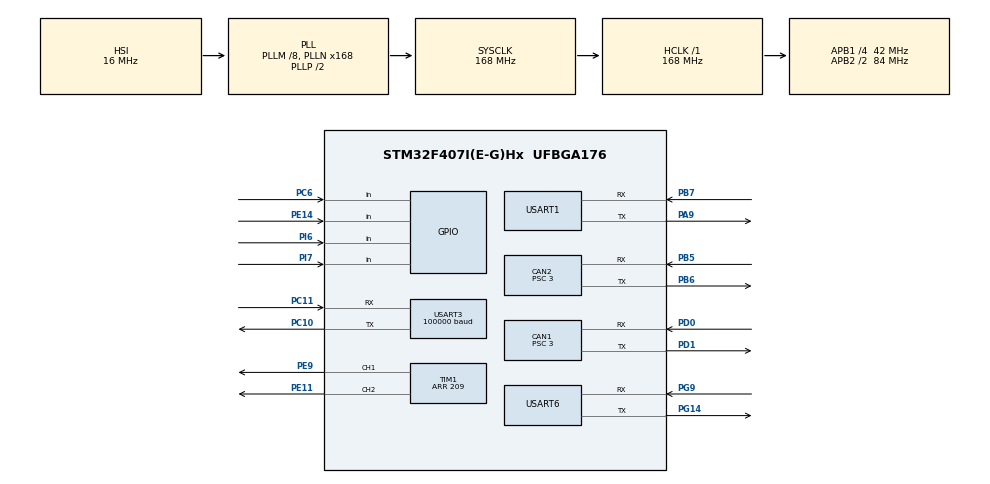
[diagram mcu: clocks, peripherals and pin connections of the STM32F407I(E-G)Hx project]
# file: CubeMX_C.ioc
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CAN1.BS1=CAN_BS1_10TQ
CAN1.BS2=CAN_BS2_3TQ
CAN1.CalculateBaudRate=1000000
CAN1.CalculateTimeBit=1000
CAN1.CalculateTimeQuantum=71.42857142857143
CAN1.Mode=CAN_MODE_NORMAL
CAN1.NART=ENABLE
CAN1.Prescaler=3
CAN1.TXFP=ENABLE
CAN2.BS1=CAN_BS1_10TQ
CAN2.BS2=CAN_BS2_3TQ
CAN2.CalculateBaudRate=1000000
CAN2.CalculateTimeBit=1000
CAN2.CalculateTimeQuantum=71.42857142857143
CAN2.NART=ENABLE
CAN2.Prescaler=3
CAN2.TXFP=ENABLE
Dma.Request0=TIM1_CH1
Dma.Request1=TIM1_CH2
Dma.Request2=USART6_RX
Dma.Request3=USART6_TX
Dma.Request4=USART1_RX
Dma.Request5=USART1_TX
Dma.Request6=USART3_RX
Dma.TIM1_CH1.0.Direction=DMA_MEMORY_TO_PERIPH
Dma.TIM1_CH1.0.FIFOMode=DMA_FIFOMODE_DISABLE
Dma.TIM1_CH1.0.Instance=DMA2_Stream3
Dma.TIM1_CH1.0.MemDataAlignment=DMA_MDATAALIGN_HALFWORD
Dma.TIM1_CH1.0.MemInc=DMA_MINC_ENABLE
Dma.TIM1_CH1.0.Mode=DMA_NORMAL
Dma.TIM1_CH1.0.PeriphDataAlignment=DMA_PDATAALIGN_HALFWORD
Dma.TIM1_CH1.0.PeriphInc=DMA_PINC_DISABLE
Dma.TIM1_CH1.0.Priority=DMA_PRIORITY_HIGH
Dma.TIM1_CH2.1.Direction=DMA_MEMORY_TO_PERIPH
Dma.TIM1_CH2.1.FIFOMode=DMA_FIFOMODE_DISABLE
Dma.TIM1_CH2.1.Instance=DMA2_Stream2
Dma.TIM1_CH2.1.MemDataAlignment=DMA_MDATAALIGN_HALFWORD
Dma.TIM1_CH2.1.MemInc=DMA_MINC_ENABLE
Dma.TIM1_CH2.1.Mode=DMA_NORMAL
Dma.TIM1_CH2.1.PeriphDataAlignment=DMA_PDATAALIGN_HALFWORD
Dma.TIM1_CH2.1.PeriphInc=DMA_PINC_DISABLE
Dma.TIM1_CH2.1.Priority=DMA_PRIORITY_HIGH
Dma.USART1_RX.4.Direction=DMA_PERIPH_TO_MEMORY
Dma.USART1_RX.4.FIFOMode=DMA_FIFOMODE_DISABLE
Dma.USART1_RX.4.Instance=DMA2_Stream5
Dma.USART1_RX.4.MemDataAlignment=DMA_MDATAALIGN_BYTE
Dma.USART1_RX.4.MemInc=DMA_MINC_ENABLE
Dma.USART1_RX.4.Mode=DMA_NORMAL
Dma.USART1_RX.4.PeriphDataAlignment=DMA_PDATAALIGN_BYTE
Dma.USART1_RX.4.PeriphInc=DMA_PINC_DISABLE
Dma.USART1_RX.4.Priority=DMA_PRIORITY_MEDIUM
Dma.USART1_TX.5.Direction=DMA_MEMORY_TO_PERIPH
Dma.USART1_TX.5.FIFOMode=DMA_FIFOMODE_DISABLE
Dma.USART1_TX.5.Instance=DMA2_Stream7
Dma.USART1_TX.5.MemDataAlignment=DMA_MDATAALIGN_BYTE
Dma.USART1_TX.5.MemInc=DMA_MINC_ENABLE
Dma.USART1_TX.5.Mode=DMA_NORMAL
Dma.USART1_TX.5.PeriphDataAlignment=DMA_PDATAALIGN_BYTE
Dma.USART1_TX.5.PeriphInc=DMA_PINC_DISABLE
Dma.USART1_TX.5.Priority=DMA_PRIORITY_MEDIUM
Dma.USART3_RX.6.Direction=DMA_PERIPH_TO_MEMORY
Dma.USART3_RX.6.FIFOMode=DMA_FIFOMODE_DISABLE
Dma.USART3_RX.6.Instance=DMA1_Stream1
Dma.USART3_RX.6.MemDataAlignment=DMA_MDATAALIGN_BYTE
Dma.USART3_RX.6.MemInc=DMA_MINC_ENABLE
Dma.USART3_RX.6.Mode=DMA_NORMAL
Dma.USART3_RX.6.PeriphDataAlignment=DMA_PDATAALIGN_BYTE
Dma.USART3_RX.6.PeriphInc=DMA_PINC_DISABLE
Dma.USART3_RX.6.Priority=DMA_PRIORITY_MEDIUM
Dma.USART6_RX.2.Direction=DMA_PERIPH_TO_MEMORY
Dma.USART6_RX.2.FIFOMode=DMA_FIFOMODE_DISABLE
Dma.USART6_RX.2.Instance=DMA2_Stream1
Dma.USART6_RX.2.MemDataAlignment=DMA_MDATAALIGN_BYTE
Dma.USART6_RX.2.MemInc=DMA_MINC_ENABLE
Dma.USART6_RX.2.Mode=DMA_NORMAL
Dma.USART6_RX.2.PeriphDataAlignment=DMA_PDATAALIGN_BYTE
Dma.USART6_RX.2.PeriphInc=DMA_PINC_DISABLE
Dma.USART6_RX.2.Priority=DMA_PRIORITY_MEDIUM
Dma.USART6_TX.3.Direction=DMA_MEMORY_TO_PERIPH
Dma.USART6_TX.3.FIFOMode=DMA_FIFOMODE_DISABLE
Dma.USART6_TX.3.Instance=DMA2_Stream6
Dma.USART6_TX.3.MemDataAlignment=DMA_MDATAALIGN_BYTE
Dma.USART6_TX.3.MemInc=DMA_MINC_ENABLE
Dma.USART6_TX.3.Mode=DMA_NORMAL
Dma.USART6_TX.3.PeriphDataAlignment=DMA_PDATAALIGN_BYTE
Dma.USART6_TX.3.PeriphInc=DMA_PINC_DISABLE
Dma.USART6_TX.3.Priority=DMA_PRIORITY_MEDIUM
FREERTOS.Tasks01=defaultTask,0,128,StartDefaultTask,Default,NULL,Dynamic,NULL,NULL;start_mission_p,-3,512,start_mission_planer_task,As weak,NULL,Dynamic,NULL,NULL
FREERTOS.configTOTAL_HEAP_SIZE=65360
Mcu.Family=STM32F4
Mcu.Name=STM32F407I(E-G)Hx
Mcu.Package=UFBGA176
NVIC.CAN1_RX0_IRQn=true\:5\:0\:true\:false\:true\:true\:true\:true\:true
NVIC.CAN2_RX0_IRQn=true\:5\:0\:true\:false\:true\:true\:true\:true\:true
NVIC.DMA1_Stream1_IRQn=true\:6\:0\:true\:false\:true\:true\:false\:true\:true
NVIC.DMA2_Stream1_IRQn=true\:6\:0\:true\:false\:true\:true\:false\:true\:true
NVIC.DMA2_Stream2_IRQn=true\:6\:0\:true\:false\:true\:true\:false\:true\:true
NVIC.DMA2_Stream3_IRQn=true\:6\:0\:true\:false\:true\:true\:false\:true\:true
NVIC.DMA2_Stream5_IRQn=true\:6\:0\:true\:false\:true\:true\:false\:true\:true
NVIC.DMA2_Stream6_IRQn=true\:6\:0\:true\:false\:true\:true\:false\:true\:true
NVIC.DMA2_Stream7_IRQn=true\:6\:0\:true\:false\:true\:true\:false\:true\:true
NVIC.PriorityGroup=NVIC_PRIORITYGROUP_4
NVIC.TIM1_BRK_TIM9_IRQn=true\:5\:0\:false\:false\:true\:true\:true\:true\:true
NVIC.TIM1_CC_IRQn=true\:5\:0\:false\:false\:true\:true\:true\:true\:true
NVIC.TIM1_TRG_COM_TIM11_IRQn=true\:5\:0\:false\:false\:true\:true\:true\:true\:true
NVIC.TIM1_UP_TIM10_IRQn=true\:5\:0\:false\:false\:true\:true\:true\:true\:true
NVIC.USART1_IRQn=true\:6\:0\:true\:false\:true\:true\:true\:true\:true
NVIC.USART3_IRQn=true\:6\:0\:true\:false\:true\:true\:true\:true\:true
NVIC.USART6_IRQn=true\:6\:0\:true\:false\:true\:true\:true\:true\:true
PA13.Mode=Serial_Wire
PA13.Signal=SYS_JTMS-SWDIO
PA14.Mode=Serial_Wire
PA14.Signal=SYS_JTCK-SWCLK
PA9.Mode=Asynchronous
PA9.Signal=USART1_TX
PB5.Mode=CAN_Activate
PB5.Signal=CAN2_RX
PB6.Mode=CAN_Activate
PB6.Signal=CAN2_TX
PB7.Mode=Asynchronous
PB7.Signal=USART1_RX
PC10.Mode=Asynchronous
PC10.Signal=USART3_TX
PC11.Mode=Asynchronous
PC11.Signal=USART3_RX
PC6.Signal=GPIO_Input
PD0.Mode=CAN_Activate
PD0.Signal=CAN1_RX
PD1.Mode=CAN_Activate
PD1.Signal=CAN1_TX
PE11.Signal=S_TIM1_CH2
PE14.Signal=GPIO_Input
PE9.Signal=S_TIM1_CH1
PG14.Mode=Asynchronous
PG14.Signal=USART6_TX
PG9.Mode=Asynchronous
PG9.Signal=USART6_RX
PH0-OSC_IN.Mode=HSE-External-Oscillator
PH0-OSC_IN.Signal=RCC_OSC_IN
PH1-OSC_OUT.Mode=HSE-External-Oscillator
PH1-OSC_OUT.Signal=RCC_OSC_OUT
PI6.Signal=GPIO_Input
PI7.Signal=GPIO_Input
ProjectManager.HeapSize=0x200
ProjectManager.StackSize=0x400
ProjectManager.TargetToolchain=CMake
RCC.48MHZClocksFreq_Value=84000000
RCC.AHBFreq_Value=168000000
RCC.APB1CLKDivider=RCC_HCLK_DIV4
RCC.APB1Freq_Value=42000000
RCC.APB1TimFreq_Value=84000000
RCC.APB2CLKDivider=RCC_HCLK_DIV2
RCC.APB2Freq_Value=84000000
RCC.APB2TimFreq_Value=168000000
RCC.CortexFreq_Value=168000000
RCC.HCLKFreq_Value=168000000
RCC.HSE_VALUE=25000000
RCC.HSI_VALUE=16000000
RCC.LSE_VALUE=32768
RCC.PLLM=8
RCC.PLLN=168
RCC.SYSCLKFreq_VALUE=168000000
RCC.SYSCLKSource=RCC_SYSCLKSOURCE_PLLCLK
RCC.VCOOutputFreq_Value=336000000
SH.S_TIM1_CH1.0=TIM1_CH1,PWM Generation1 CH1
SH.S_TIM1_CH2.0=TIM1_CH2,PWM Generation2 CH2
TIM1.Channel-PWM\ Generation1\ CH1=TIM_CHANNEL_1
TIM1.Channel-PWM\ Generation2\ CH2=TIM_CHANNEL_2
TIM1.Period=209
USART1.VirtualMode=VM_ASYNC
USART3.BaudRate=100000
USART3.Mode=MODE_RX
USART3.Parity=PARITY_EVEN
USART3.StopBits=STOPBITS_2
USART3.VirtualMode=VM_ASYNC
USART6.VirtualMode=VM_ASYNC
VP_FREERTOS_VS_CMSIS_V1.Mode=CMSIS_V1
VP_RTC_VS_RTC_Activate.Mode=RTC_Enabled
VP_RTC_VS_RTC_Calendar.Mode=RTC_Calendar
VP_TIM1_VS_ClockSourceINT.Mode=Internal
board=custom

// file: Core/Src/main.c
/* USER CODE BEGIN Header */
/**
  ******************************************************************************
  * @file           : main.c
  * @brief          : Main program body
  ******************************************************************************
  * @attention
  *
  * Copyright (c) 2026 STMicroelectronics.
  * All rights reserved.
  *
  * This software is licensed under terms that can be found in the LICENSE file
  * in the root directory of this software component.
  * If no LICENSE file comes with this software, it is provided AS-IS.
  *
  ******************************************************************************
  */
/* USER CODE END Header */
#include "main.h"
#include "cmsis_os.h"
#include "can.h"
#include "dma.h"
#include "rtc.h"
#include "tim.h"
#include "usart.h"
#include "gpio.h"

/* USER CODE BEGIN Includes */
#include "SEGGER_RTT.h"
#include "log.h"

/* USER CODE END Includes */

void SystemClock_Config(void);
void MX_FREERTOS_Init(void);

int main(void)
{

  /* USER CODE BEGIN 1 */
  /* 初始化 RTT 控制块：写入 "SEGGER RTT" 标识与缓冲区指针。
   * 必须在 HAL_Init() 之前，且早于任何日志输出，否则调试器搜不到控制块。
   * 只做内存写入，不依赖时钟/中断/HAL。 */

  /* USER CODE END 1 */

  /* MCU Configuration--------------------------------------------------------*/

  /* Reset of all peripherals, Initializes the Flash interface and the Systick. */
  HAL_Init();

  /* USER CODE BEGIN Init */
    SEGGER_RTT_Init();
    LogHandle.Ctrl.Init();

  /* USER CODE END Init */

  /* Configure the system clock */
  SystemClock_Config();

  /* Initialize all configured peripherals */
  MX_GPIO_Init();
  MX_DMA_Init();
  MX_CAN1_Init();
  MX_CAN2_Init();
  MX_USART1_UART_Init();
  MX_USART6_UART_Init();
  MX_TIM1_Init();
  MX_USART3_UART_Init();
  MX_RTC_Init();

  /* Call init function for freertos objects (in cmsis_os2.c) */
  MX_FREERTOS_Init();

  /* Start scheduler */
  osKernelStart();

  /* We should never get here as control is now taken by the scheduler */

  /* Infinite loop */
  while (1)
  {

  }
}

void SystemClock_Config(void)
{
  RCC_OscInitTypeDef RCC_OscInitStruct = {0};
  RCC_ClkInitTypeDef RCC_ClkInitStruct = {0};

  /** Configure the main internal regulator output voltage
  */
  __HAL_RCC_PWR_CLK_ENABLE();
  __HAL_PWR_VOLTAGESCALING_CONFIG(PWR_REGULATOR_VOLTAGE_SCALE1);

  /** Initializes the RCC Oscillators according to the specified parameters
  * in the RCC_OscInitTypeDef structure.
  */
  RCC_OscInitStruct.OscillatorType = RCC_OSCILLATORTYPE_HSI|RCC_OSCILLATORTYPE_LSI;
  RCC_OscInitStruct.HSIState = RCC_HSI_ON;
  RCC_OscInitStruct.HSICalibrationValue = RCC_HSICALIBRATION_DEFAULT;
  RCC_OscInitStruct.LSIState = RCC_LSI_ON;
  RCC_OscInitStruct.PLL.PLLState = RCC_PLL_ON;
  RCC_OscInitStruct.PLL.PLLSource = RCC_PLLSOURCE_HSI;
  RCC_OscInitStruct.PLL.PLLM = 8;
  RCC_OscInitStruct.PLL.PLLN = 168;
  RCC_OscInitStruct.PLL.PLLP = RCC_PLLP_DIV2;
  RCC_OscInitStruct.PLL.PLLQ = 4;
  if (HAL_RCC_OscConfig(&RCC_OscInitStruct) != HAL_OK)
  {
    Error_Handler();
  }

  /** Initializes the CPU, AHB and APB buses clocks
  */
  RCC_ClkInitStruct.ClockType = RCC_CLOCKTYPE_HCLK|RCC_CLOCKTYPE_SYSCLK
                              |RCC_CLOCKTYPE_PCLK1|RCC_CLOCKTYPE_PCLK2;
  RCC_ClkInitStruct.SYSCLKSource = RCC_SYSCLKSOURCE_PLLCLK;
  RCC_ClkInitStruct.AHBCLKDivider = RCC_SYSCLK_DIV1;
  RCC_ClkInitStruct.APB1CLKDivider = RCC_HCLK_DIV4;
  RCC_ClkInitStruct.APB2CLKDivider = RCC_HCLK_DIV2;

  if (HAL_RCC_ClockConfig(&RCC_ClkInitStruct, FLASH_LATENCY_5) != HAL_OK)
  {
    Error_Handler();
  }
}

void Error_Handler(void)
{
  __disable_irq();
  while (1)
  {
  }
}

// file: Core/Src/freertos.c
/* USER CODE BEGIN Header */
/**
  ******************************************************************************
  * File Name          : freertos.c
  * Description        : Code for freertos applications
  ******************************************************************************
  * @attention
  *
  * Copyright (c) 2026 STMicroelectronics.
  * All rights reserved.
  *
  * This software is licensed under terms that can be found in the LICENSE file
  * in the root directory of this software component.
  * If no LICENSE file comes with this software, it is provided AS-IS.
  *
  ******************************************************************************
  */
/* USER CODE END Header */

#include "FreeRTOS.h"
#include "task.h"
#include "main.h"
#include "cmsis_os.h"

osThreadId defaultTaskHandle;
osThreadId start_mission_pHandle;

void StartDefaultTask(void const * argument);
void start_mission_planer_task(void const * argument);

void MX_FREERTOS_Init(void); /* (MISRA C 2004 rule 8.1) */

/* GetIdleTaskMemory prototype (linked to static allocation support) */
void vApplicationGetIdleTaskMemory( StaticTask_t **ppxIdleTaskTCBBuffer, StackType_t **ppxIdleTaskStackBuffer, uint32_t *pulIdleTaskStackSize );

/* USER CODE BEGIN GET_IDLE_TASK_MEMORY */
static StaticTask_t xIdleTaskTCBBuffer;
static StackType_t xIdleStack[configMINIMAL_STACK_SIZE];

void vApplicationGetIdleTaskMemory( StaticTask_t **ppxIdleTaskTCBBuffer, StackType_t **ppxIdleTaskStackBuffer, uint32_t *pulIdleTaskStackSize )
{
  *ppxIdleTaskTCBBuffer = &xIdleTaskTCBBuffer;
  *ppxIdleTaskStackBuffer = &xIdleStack[0];
  *pulIdleTaskStackSize = configMINIMAL_STACK_SIZE;
  /* place for user code */
}
/* USER CODE END GET_IDLE_TASK_MEMORY */

void MX_FREERTOS_Init(void) {

  /* Create the thread(s) */
  /* definition and creation of defaultTask */
  osThreadDef(defaultTask, StartDefaultTask, osPriorityNormal, 0, 128);
  defaultTaskHandle = osThreadCreate(osThread(defaultTask), NULL);

  /* definition and creation of start_mission_p */
  osThreadDef(start_mission_p, start_mission_planer_task, osPriorityIdle, 0, 512);
  start_mission_pHandle = osThreadCreate(osThread(start_mission_p), NULL);

}

void StartDefaultTask(void const * argument)
{
  for(;;)
  {
    osDelay(1);
  }
}

__weak void start_mission_planer_task(void const * argument)
{
  for(;;)
  {
    osDelay(1);
  }
}
